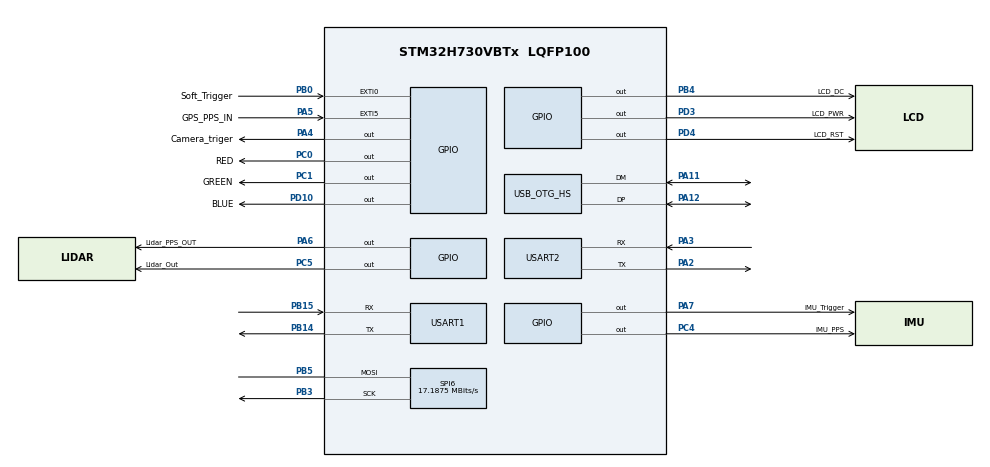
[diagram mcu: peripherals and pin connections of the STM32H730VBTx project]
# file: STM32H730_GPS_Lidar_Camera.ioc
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CORTEX_M7.CPU_DCache=Enabled
CORTEX_M7.CPU_ICache=Enabled
CORTEX_M7.Enable_S-Cortex_Memory_Protection_Unit_Region1_Settings_S=__NULL
CORTEX_M7.default_mode_Activation=1
Dma.Request0=USART1_RX
Dma.Request1=USART2_TX
Dma.USART1_RX.0.Direction=DMA_PERIPH_TO_MEMORY
Dma.USART1_RX.0.EventEnable=DISABLE
Dma.USART1_RX.0.FIFOMode=DMA_FIFOMODE_DISABLE
Dma.USART1_RX.0.Instance=DMA1_Stream0
Dma.USART1_RX.0.MemDataAlignment=DMA_MDATAALIGN_BYTE
Dma.USART1_RX.0.MemInc=DMA_MINC_ENABLE
Dma.USART1_RX.0.Mode=DMA_NORMAL
Dma.USART1_RX.0.PeriphDataAlignment=DMA_PDATAALIGN_BYTE
Dma.USART1_RX.0.PeriphInc=DMA_PINC_DISABLE
Dma.USART1_RX.0.Polarity=HAL_DMAMUX_REQ_GEN_RISING
Dma.USART1_RX.0.Priority=DMA_PRIORITY_HIGH
Dma.USART1_RX.0.RequestNumber=1
Dma.USART1_RX.0.SignalID=NONE
Dma.USART1_RX.0.SyncEnable=DISABLE
Dma.USART1_RX.0.SyncPolarity=HAL_DMAMUX_SYNC_NO_EVENT
Dma.USART1_RX.0.SyncRequestNumber=1
Dma.USART1_RX.0.SyncSignalID=NONE
Dma.USART2_TX.1.Direction=DMA_MEMORY_TO_PERIPH
Dma.USART2_TX.1.EventEnable=DISABLE
Dma.USART2_TX.1.FIFOMode=DMA_FIFOMODE_DISABLE
Dma.USART2_TX.1.Instance=DMA1_Stream1
Dma.USART2_TX.1.MemDataAlignment=DMA_MDATAALIGN_BYTE
Dma.USART2_TX.1.MemInc=DMA_MINC_ENABLE
Dma.USART2_TX.1.Mode=DMA_NORMAL
Dma.USART2_TX.1.PeriphDataAlignment=DMA_PDATAALIGN_BYTE
Dma.USART2_TX.1.PeriphInc=DMA_PINC_DISABLE
Dma.USART2_TX.1.Polarity=HAL_DMAMUX_REQ_GEN_RISING
Dma.USART2_TX.1.Priority=DMA_PRIORITY_MEDIUM
Dma.USART2_TX.1.RequestNumber=1
Dma.USART2_TX.1.SignalID=NONE
Dma.USART2_TX.1.SyncEnable=DISABLE
Dma.USART2_TX.1.SyncPolarity=HAL_DMAMUX_SYNC_NO_EVENT
Dma.USART2_TX.1.SyncRequestNumber=1
Dma.USART2_TX.1.SyncSignalID=NONE
Mcu.Family=STM32H7
Mcu.Name=STM32H730VBTx
Mcu.Package=LQFP100
NVIC.DMA1_Stream0_IRQn=true\:1\:0\:true\:false\:true\:true\:false\:true\:true
NVIC.DMA1_Stream1_IRQn=true\:0\:0\:false\:false\:true\:true\:false\:true\:true
NVIC.EXTI0_IRQn=true\:9\:0\:true\:false\:true\:false\:true\:true\:true
NVIC.EXTI9_5_IRQn=true\:8\:0\:true\:false\:true\:false\:true\:true\:true
NVIC.OTG_HS_EP1_IN_IRQn=true\:10\:0\:true\:false\:true\:false\:true\:true\:true
NVIC.OTG_HS_EP1_OUT_IRQn=true\:10\:0\:true\:false\:true\:false\:true\:true\:true
NVIC.OTG_HS_IRQn=true\:10\:0\:true\:false\:true\:false\:false\:true\:true
NVIC.PriorityGroup=NVIC_PRIORITYGROUP_4
NVIC.TIM1_UP_IRQn=true\:15\:0\:false\:false\:true\:false\:false\:true\:true
NVIC.TimeBase=TIM1_UP_IRQn
NVIC.TimeBaseIP=TIM1
NVIC.USART1_IRQn=true\:1\:0\:true\:false\:true\:false\:true\:true\:true
NVIC.USART2_IRQn=true\:7\:0\:true\:false\:true\:false\:true\:true\:true
PA11.Mode=Device_Only_FS
PA11.Signal=USB_OTG_HS_DM
PA12.Mode=Device_Only_FS
PA12.Signal=USB_OTG_HS_DP
PA13(JTMS/SWDIO).Mode=Serial_Wire
PA13(JTMS/SWDIO).Signal=DEBUG_JTMS-SWDIO
PA14(JTCK/SWCLK).Mode=Serial_Wire
PA14(JTCK/SWCLK).Signal=DEBUG_JTCK-SWCLK
PA2.GPIO_PuPd=GPIO_PULLUP
PA2.GPIO_Speed=GPIO_SPEED_FREQ_HIGH
PA2.Mode=Asynchronous
PA2.Signal=USART2_TX
PA3.GPIO_PuPd=GPIO_PULLUP
PA3.GPIO_Speed=GPIO_SPEED_FREQ_HIGH
PA3.Mode=Asynchronous
PA3.Signal=USART2_RX
PA4.GPIO_Label=Camera_triger
PA4.GPIO_PuPd=GPIO_PULLUP
PA4.GPIO_Speed=GPIO_SPEED_FREQ_HIGH
PA4.PinState=GPIO_PIN_SET
PA4.Signal=GPIO_Output
PA5.GPIO_Label=GPS_PPS_IN
PA5.GPIO_ModeDefaultEXTI=GPIO_MODE_IT_FALLING
PA5.GPIO_PuPd=GPIO_PULLUP
PA5.Signal=GPXTI5
PA6.GPIO_Label=Lidar_PPS_OUT
PA6.GPIO_ModeDefaultOutputPP=GPIO_MODE_OUTPUT_PP
PA6.GPIO_PuPd=GPIO_PULLUP
PA6.GPIO_Speed=GPIO_SPEED_FREQ_HIGH
PA6.PinState=GPIO_PIN_SET
PA6.Signal=GPIO_Output
PA7.GPIO_Label=IMU_Trigger
PA7.GPIO_ModeDefaultOutputPP=GPIO_MODE_OUTPUT_PP
PA7.GPIO_PuPd=GPIO_PULLUP
PA7.Signal=GPIO_Output
PB0.GPIO_Label=Soft_Trigger
PB0.GPIO_ModeDefaultEXTI=GPIO_MODE_IT_FALLING
PB0.GPIO_PuPd=GPIO_PULLUP
PB0.Signal=GPXTI0
PB14.GPIO_PuPd=GPIO_PULLUP
PB14.GPIO_Speed=GPIO_SPEED_FREQ_HIGH
PB14.Mode=Asynchronous
PB14.Signal=USART1_TX
PB15.GPIO_PuPd=GPIO_PULLUP
PB15.GPIO_Speed=GPIO_SPEED_FREQ_HIGH
PB15.Mode=Asynchronous
PB15.Signal=USART1_RX
PB3(JTDO/TRACESWO).Mode=Simplex_Bidirectional_Master
PB3(JTDO/TRACESWO).Signal=SPI6_SCK
PB4(NJTRST).GPIO_Label=LCD_DC
PB4(NJTRST).GPIO_PuPd=GPIO_PULLUP
PB4(NJTRST).Signal=GPIO_Output
PB5.Mode=Simplex_Bidirectional_Master
PB5.Signal=SPI6_MOSI
PC0.GPIO_Label=RED
PC0.GPIO_PuPd=GPIO_PULLUP
PC0.PinState=GPIO_PIN_SET
PC0.Signal=GPIO_Output
PC1.GPIO_Label=GREEN
PC1.GPIO_PuPd=GPIO_PULLUP
PC1.PinState=GPIO_PIN_SET
PC1.Signal=GPIO_Output
PC4.GPIO_Label=IMU_PPS
PC4.GPIO_PuPd=GPIO_PULLUP
PC4.PinState=GPIO_PIN_SET
PC4.Signal=GPIO_Output
PC5.GPIO_Label=Lidar_Out
PC5.GPIO_PuPd=GPIO_PULLUP
PC5.Signal=GPIO_Output
PD10.GPIO_Label=BLUE
PD10.GPIO_PuPd=GPIO_PULLUP
PD10.PinState=GPIO_PIN_SET
PD10.Signal=GPIO_Output
PD3.GPIO_Label=LCD_PWR
PD3.GPIO_PuPd=GPIO_PULLUP
PD3.Signal=GPIO_Output
PD4.GPIO_Label=LCD_RST
PD4.GPIO_PuPd=GPIO_PULLUP
PD4.Signal=GPIO_Output
PH0-OSC_IN.Mode=HSE-External-Oscillator
PH0-OSC_IN.Signal=RCC_OSC_IN
PH1-OSC_OUT.Mode=HSE-External-Oscillator
PH1-OSC_OUT.Signal=RCC_OSC_OUT
ProjectManager.HeapSize=0x1000
ProjectManager.StackSize=0x1000
ProjectManager.TargetToolchain=STM32CubeIDE
RCC.ADCFreq_Value=50390625
RCC.APB1Freq_Value=137500000
RCC.APB2Freq_Value=137500000
RCC.APB3Freq_Value=137500000
RCC.APB4Freq_Value=137500000
RCC.CortexFreq_Value=550000000
RCC.D1PPRE=RCC_APB3_DIV2
RCC.D2PPRE1=RCC_APB1_DIV2
RCC.D2PPRE2=RCC_APB2_DIV2
RCC.D3PPRE=RCC_APB4_DIV2
RCC.DIVM1=2
RCC.DIVM3=25
RCC.DIVN1=44
RCC.DIVN3=192
RCC.DIVP1=1
RCC.DIVQ3=4
RCC.HCLKFreq_Value=275000000
RCC.HPRE=RCC_HCLK_DIV2
RCC.PLLSourceVirtual=RCC_PLLSOURCE_HSE
RCC.SYSCLKFreq_VALUE=550000000
RCC.SYSCLKSource=RCC_SYSCLKSOURCE_PLLCLK
RCC.USBCLockSelection=RCC_USBCLKSOURCE_PLL3
RCC.USBFreq_Value=48000000
SEGGER.I-CUBE-embOS.1.3.1.embOSCcRTOSJjembOSOoAPIOoconfiguration=CMSISAaRTOS
SEGGER.I-CUBE-embOS.1.3.1.embOSCcRTOSJjembOSOokernelOoconfiguration=DebugOoandOoTrace
SPI6.BaudRatePrescaler=SPI_BAUDRATEPRESCALER_8
SPI6.CLKPhase=SPI_PHASE_2EDGE
SPI6.CLKPolarity=SPI_POLARITY_HIGH
SPI6.CalculateBaudRate=17.1875 MBits/s
SPI6.DataSize=SPI_DATASIZE_8BIT
SPI6.Direction=SPI_DIRECTION_1LINE
SPI6.Mode=SPI_MODE_MASTER
SPI6.VirtualType=VM_MASTER
USART1.VirtualMode-Asynchronous=VM_ASYNC
USART2.VirtualMode-Asynchronous=VM_ASYNC
USB_DEVICE.CLASS_NAME_HS=CUSTOM_HID
USB_DEVICE.CUSTOM_HID_HS_BINTERVAL=0x1
USB_DEVICE.PID_CUSTOMHID_HS=0x1234
USB_DEVICE.USBD_CUSTOM_HID_REPORT_DESC_SIZE=20
USB_DEVICE.VID=0xabcd
USB_DEVICE.VirtualMode=CustomHid
USB_DEVICE.VirtualModeHS=Custom_Hid_HS
USB_OTG_HS.VirtualMode-Device_Only_FS=Device_Only_FS
VP_SEGGER.I-CUBE-embOS_VS_RTOSJjembOS_1.1.0_1.3.1.Mode=RTOSJjembOS
VP_SYS_VS_tim1.Mode=TIM1
VP_USB_DEVICE_VS_USB_DEVICE_CUSTOM_HID_HS.Mode=CUSTOM_HID_HS
board=custom

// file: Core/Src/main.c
/* USER CODE BEGIN Header */
/**
  ******************************************************************************
  * @file           : main.c
  * @brief          : Main program body
  ******************************************************************************
  * @attention
  *
  * Copyright (c) 2023 STMicroelectronics.
  * All rights reserved.
  *
  * This software is licensed under terms that can be found in the LICENSE file
  * in the root directory of this software component.
  * If no LICENSE file comes with this software, it is provided AS-IS.
  *
  ******************************************************************************
  */
/* USER CODE END Header */
#include "main.h"
/* Scheduler includes. */
#include "RTOS.h"

#include "dma.h"
#include "spi.h"
#include "usart.h"
#include "usb_device.h"
#include "gpio.h"

/* USER CODE BEGIN Includes */
#include "SEGGER_SYSVIEW.h"
#include "camera_trigger_task.h"
#include "lidar_message_task.h"
/* USER CODE END Includes */

/* USER CODE BEGIN PTD */
static OS_STACKPTR int StackLidar[1024], StackCamera[256];
static OS_TASK     TCBLidar, TCBCamera;
/* USER CODE END PTD */

void SystemClock_Config(void);
static void MPU_Initialize(void);
static void MPU_Config(void);

int main(void)
{

  /* Enable I-Cache---------------------------------------------------------*/
  SCB_EnableICache();

  /* Enable D-Cache---------------------------------------------------------*/
  SCB_EnableDCache();

  /* MCU Configuration--------------------------------------------------------*/

  /* Reset of all peripherals, Initializes the Flash interface and the Systick. */
  HAL_Init();

  /* MPU Configuration--------------------------------------------------------*/
  MPU_Config();

  /* Configure the system clock */
  SystemClock_Config();

  /* USER CODE BEGIN SysInit */
  OS_Init();

  /* USER CODE END SysInit */

  /* Initialize all configured peripherals */
  MX_GPIO_Init();
  MX_DMA_Init();
  MX_USB_DEVICE_Init();
  MX_USART2_UART_Init();
  MX_SPI6_Init();
  MX_USART1_UART_Init();
  /* USER CODE BEGIN 2 */
  OS_InitHW();
#ifdef DEBUG
  SEGGER_SYSVIEW_Conf();
#endif
  OS_TASK_CREATE(&TCBLidar, "Lidar Send", 2, lidar_message_task, StackLidar);
  OS_TASK_CREATE(&TCBCamera, "Camera USB", 1, camera_utc_task, StackCamera);
  /* USER CODE END 2 */

  /* Initialize the embOS kernel and configure the hardware parameters for embOS */

  /* Start embOS */
  OS_Start();

  /* Infinite loop */
  while (1)
  {

  }
}

void SystemClock_Config(void)
{
  RCC_OscInitTypeDef RCC_OscInitStruct = {0};
  RCC_ClkInitTypeDef RCC_ClkInitStruct = {0};

  /** Supply configuration update enable
  */
  HAL_PWREx_ConfigSupply(PWR_LDO_SUPPLY);

  /** Configure the main internal regulator output voltage
  */
  __HAL_PWR_VOLTAGESCALING_CONFIG(PWR_REGULATOR_VOLTAGE_SCALE0);

  while(!__HAL_PWR_GET_FLAG(PWR_FLAG_VOSRDY)) {}

  /** Initializes the RCC Oscillators according to the specified parameters
  * in the RCC_OscInitTypeDef structure.
  */
  RCC_OscInitStruct.OscillatorType = RCC_OSCILLATORTYPE_HSE;
  RCC_OscInitStruct.HSEState = RCC_HSE_ON;
  RCC_OscInitStruct.PLL.PLLState = RCC_PLL_ON;
  RCC_OscInitStruct.PLL.PLLSource = RCC_PLLSOURCE_HSE;
  RCC_OscInitStruct.PLL.PLLM = 2;
  RCC_OscInitStruct.PLL.PLLN = 44;
  RCC_OscInitStruct.PLL.PLLP = 1;
  RCC_OscInitStruct.PLL.PLLQ = 2;
  RCC_OscInitStruct.PLL.PLLR = 2;
  RCC_OscInitStruct.PLL.PLLRGE = RCC_PLL1VCIRANGE_3;
  RCC_OscInitStruct.PLL.PLLVCOSEL = RCC_PLL1VCOWIDE;
  RCC_OscInitStruct.PLL.PLLFRACN = 0;
  if (HAL_RCC_OscConfig(&RCC_OscInitStruct) != HAL_OK)
  {
    Error_Handler();
  }

  /** Initializes the CPU, AHB and APB buses clocks
  */
  RCC_ClkInitStruct.ClockType = RCC_CLOCKTYPE_HCLK|RCC_CLOCKTYPE_SYSCLK
                              |RCC_CLOCKTYPE_PCLK1|RCC_CLOCKTYPE_PCLK2
                              |RCC_CLOCKTYPE_D3PCLK1|RCC_CLOCKTYPE_D1PCLK1;
  RCC_ClkInitStruct.SYSCLKSource = RCC_SYSCLKSOURCE_PLLCLK;
  RCC_ClkInitStruct.SYSCLKDivider = RCC_SYSCLK_DIV1;
  RCC_ClkInitStruct.AHBCLKDivider = RCC_HCLK_DIV2;
  RCC_ClkInitStruct.APB3CLKDivider = RCC_APB3_DIV2;
  RCC_ClkInitStruct.APB1CLKDivider = RCC_APB1_DIV2;
  RCC_ClkInitStruct.APB2CLKDivider = RCC_APB2_DIV2;
  RCC_ClkInitStruct.APB4CLKDivider = RCC_APB4_DIV2;

  if (HAL_RCC_ClockConfig(&RCC_ClkInitStruct, FLASH_LATENCY_3) != HAL_OK)
  {
    Error_Handler();
  }
}

/* MPU Configuration */

void MPU_Config(void)
{
  MPU_Region_InitTypeDef MPU_InitStruct = {0};

  /* Disables the MPU */
  HAL_MPU_Disable();

  /** Initializes and configures the Region and the memory to be protected
  */
  MPU_InitStruct.Enable = MPU_REGION_ENABLE;
  MPU_InitStruct.Number = MPU_REGION_NUMBER0;
  MPU_InitStruct.BaseAddress = 0x0;
  MPU_InitStruct.Size = MPU_REGION_SIZE_4GB;
  MPU_InitStruct.SubRegionDisable = 0x87;
  MPU_InitStruct.TypeExtField = MPU_TEX_LEVEL0;
  MPU_InitStruct.AccessPermission = MPU_REGION_NO_ACCESS;
  MPU_InitStruct.DisableExec = MPU_INSTRUCTION_ACCESS_DISABLE;
  MPU_InitStruct.IsShareable = MPU_ACCESS_SHAREABLE;
  MPU_InitStruct.IsCacheable = MPU_ACCESS_NOT_CACHEABLE;
  MPU_InitStruct.IsBufferable = MPU_ACCESS_NOT_BUFFERABLE;

  HAL_MPU_ConfigRegion(&MPU_InitStruct);
  /* Enables the MPU */
  HAL_MPU_Enable(MPU_PRIVILEGED_DEFAULT);

}

void HAL_TIM_PeriodElapsedCallback(TIM_HandleTypeDef *htim)
{
  if (htim->Instance == TIM1) {
    HAL_IncTick();
  }
}

void Error_Handler(void)
{
  __disable_irq();
  while (1)
  {
  }
}
